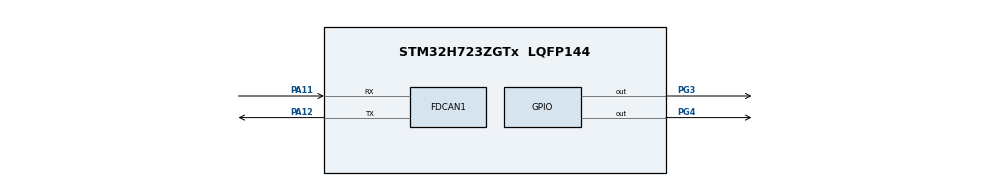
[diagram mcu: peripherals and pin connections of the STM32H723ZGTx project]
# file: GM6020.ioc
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CORTEX_M7.default_mode_Activation=1
FDCAN1.AutoRetransmission=ENABLE
FDCAN1.CalculateBaudRateNominal=1000000
FDCAN1.CalculateTimeBitNominal=1000
FDCAN1.CalculateTimeQuantumNominal=8.0
FDCAN1.NominalPrescaler=1
FDCAN1.NominalTimeSeg1=99
FDCAN1.NominalTimeSeg2=25
FDCAN1.RxFifo0ElmtsNbr=1
FDCAN1.StdFiltersNbr=1
FDCAN1.TxFifoQueueElmtsNbr=1
Mcu.Family=STM32H7
Mcu.Name=STM32H723ZGTx
Mcu.Package=LQFP144
NVIC.FDCAN1_IT0_IRQn=true\:0\:0\:false\:false\:true\:true\:true\:true
NVIC.PriorityGroup=NVIC_PRIORITYGROUP_4
PA11.Mode=FDCAN_Activate
PA11.Signal=FDCAN1_RX
PA12.Mode=FDCAN_Activate
PA12.Signal=FDCAN1_TX
PA13(JTMS/SWDIO).Mode=Serial_Wire
PA13(JTMS/SWDIO).Signal=DEBUG_JTMS-SWDIO
PA14(JTCK/SWCLK).Mode=Serial_Wire
PA14(JTCK/SWCLK).Signal=DEBUG_JTCK-SWCLK
PG3.PinState=GPIO_PIN_RESET
PG3.Signal=GPIO_Output
PG4.GPIO_Speed=GPIO_SPEED_FREQ_LOW
PG4.Signal=GPIO_Output
PH0-OSC_IN.Mode=HSE-External-Oscillator
PH0-OSC_IN.Signal=RCC_OSC_IN
PH1-OSC_OUT.Mode=HSE-External-Oscillator
PH1-OSC_OUT.Signal=RCC_OSC_OUT
ProjectManager.HeapSize=0x200
ProjectManager.StackSize=0x400
ProjectManager.TargetToolchain=STM32CubeIDE
RCC.ADCFreq_Value=50390625
RCC.APB1Freq_Value=125000000
RCC.APB2Freq_Value=125000000
RCC.APB3Freq_Value=125000000
RCC.APB4Freq_Value=125000000
RCC.CortexFreq_Value=500000000
RCC.D1PPRE=RCC_APB3_DIV2
RCC.D2PPRE1=RCC_APB1_DIV2
RCC.D2PPRE2=RCC_APB2_DIV2
RCC.D3PPRE=RCC_APB4_DIV2
RCC.DIVM1=2
RCC.DIVN1=40
RCC.DIVP1=1
RCC.DIVQ1=4
RCC.HCLKFreq_Value=250000000
RCC.HPRE=RCC_HCLK_DIV2
RCC.PLLFRACN=0
RCC.PLLSourceVirtual=RCC_PLLSOURCE_HSE
RCC.SYSCLKFreq_VALUE=500000000
RCC.SYSCLKSource=RCC_SYSCLKSOURCE_PLLCLK
RCC.USBFreq_Value=125000000
VP_MEMORYMAP_VS_MEMORYMAP.Mode=CurAppReg
board=custom

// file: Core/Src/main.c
/* USER CODE BEGIN Header */
/**
  ******************************************************************************
  * @file           : main.c
  * @brief          : Main program body
  ******************************************************************************
  * @attention
  *
  * Copyright (c) 2026 STMicroelectronics.
  * All rights reserved.
  *
  * This software is licensed under terms that can be found in the LICENSE file
  * in the root directory of this software component.
  * If no LICENSE file comes with this software, it is provided AS-IS.
  *
  ******************************************************************************
  */
/* USER CODE END Header */
#include "main.h"
#include "GM6020.h"

FDCAN_HandleTypeDef hfdcan1;

void SystemClock_Config(void);
static void MPU_Config(void);
static void MX_GPIO_Init(void);
static void MX_FDCAN1_Init(void);

int main(void)
{

  /* MPU Configuration--------------------------------------------------------*/
  MPU_Config();

  /* MCU Configuration--------------------------------------------------------*/

  /* Reset of all peripherals, Initializes the Flash interface and the Systick. */
  HAL_Init();

  /* Configure the system clock */
  SystemClock_Config();

  /* Initialize all configured peripherals */
  MX_GPIO_Init();
  MX_FDCAN1_Init();
  /* USER CODE BEGIN 2 */

  GM6020_Init();
  HAL_Delay(3000);

  HAL_GPIO_WritePin(GPIOG, GPIO_PIN_4, GPIO_PIN_SET);

  HAL_Delay(1000);

  //让电机转 180°
  GM6020_Turn_Degrees(180.0f);

//在等待循环中持续调用GM6020_Update
  uint32_t timeout = 3000;  // 最多等待3秒(超时保护)
  while (fabsf(GM6020_Get_Target_Angle() - GM6020_Get_Current_Angle()) > 1.0f && timeout > 0) {
      GM6020_Update();
      HAL_Delay(1);
      timeout--;
  }

  //额外等1s确保电机到位
  HAL_Delay(1000);

  HAL_GPIO_WritePin(GPIOG, GPIO_PIN_4, GPIO_PIN_RESET);
  /* USER CODE END 2 */

  /* Infinite loop */
  /* USER CODE BEGIN WHILE */
  while (1)
  {
	  GM6020_Update();
	  HAL_Delay(1);
    /* USER CODE END WHILE */

  }
}

void SystemClock_Config(void)
{
  RCC_OscInitTypeDef RCC_OscInitStruct = {0};
  RCC_ClkInitTypeDef RCC_ClkInitStruct = {0};

  /** Supply configuration update enable
  */
  HAL_PWREx_ConfigSupply(PWR_LDO_SUPPLY);

  /** Configure the main internal regulator output voltage
  */
  __HAL_PWR_VOLTAGESCALING_CONFIG(PWR_REGULATOR_VOLTAGE_SCALE0);

  while(!__HAL_PWR_GET_FLAG(PWR_FLAG_VOSRDY)) {}

  /** Initializes the RCC Oscillators according to the specified parameters
  * in the RCC_OscInitTypeDef structure.
  */
  RCC_OscInitStruct.OscillatorType = RCC_OSCILLATORTYPE_HSE;
  RCC_OscInitStruct.HSEState = RCC_HSE_ON;
  RCC_OscInitStruct.PLL.PLLState = RCC_PLL_ON;
  RCC_OscInitStruct.PLL.PLLSource = RCC_PLLSOURCE_HSE;
  RCC_OscInitStruct.PLL.PLLM = 2;
  RCC_OscInitStruct.PLL.PLLN = 40;
  RCC_OscInitStruct.PLL.PLLP = 1;
  RCC_OscInitStruct.PLL.PLLQ = 4;
  RCC_OscInitStruct.PLL.PLLR = 2;
  RCC_OscInitStruct.PLL.PLLRGE = RCC_PLL1VCIRANGE_3;
  RCC_OscInitStruct.PLL.PLLVCOSEL = RCC_PLL1VCOWIDE;
  RCC_OscInitStruct.PLL.PLLFRACN = 0;
  if (HAL_RCC_OscConfig(&RCC_OscInitStruct) != HAL_OK)
  {
    Error_Handler();
  }

  /** Initializes the CPU, AHB and APB buses clocks
  */
  RCC_ClkInitStruct.ClockType = RCC_CLOCKTYPE_HCLK|RCC_CLOCKTYPE_SYSCLK
                              |RCC_CLOCKTYPE_PCLK1|RCC_CLOCKTYPE_PCLK2
                              |RCC_CLOCKTYPE_D3PCLK1|RCC_CLOCKTYPE_D1PCLK1;
  RCC_ClkInitStruct.SYSCLKSource = RCC_SYSCLKSOURCE_PLLCLK;
  RCC_ClkInitStruct.SYSCLKDivider = RCC_SYSCLK_DIV1;
  RCC_ClkInitStruct.AHBCLKDivider = RCC_HCLK_DIV2;
  RCC_ClkInitStruct.APB3CLKDivider = RCC_APB3_DIV2;
  RCC_ClkInitStruct.APB1CLKDivider = RCC_APB1_DIV2;
  RCC_ClkInitStruct.APB2CLKDivider = RCC_APB2_DIV2;
  RCC_ClkInitStruct.APB4CLKDivider = RCC_APB4_DIV2;

  if (HAL_RCC_ClockConfig(&RCC_ClkInitStruct, FLASH_LATENCY_3) != HAL_OK)
  {
    Error_Handler();
  }
}

static void MX_FDCAN1_Init(void)
{

  hfdcan1.Instance = FDCAN1;
  hfdcan1.Init.FrameFormat = FDCAN_FRAME_CLASSIC;
  hfdcan1.Init.Mode = FDCAN_MODE_NORMAL;
  hfdcan1.Init.AutoRetransmission = ENABLE;
  hfdcan1.Init.TransmitPause = DISABLE;
  hfdcan1.Init.ProtocolException = DISABLE;
  hfdcan1.Init.NominalPrescaler = 1;
  hfdcan1.Init.NominalSyncJumpWidth = 1;
  hfdcan1.Init.NominalTimeSeg1 = 99;
  hfdcan1.Init.NominalTimeSeg2 = 25;
  hfdcan1.Init.DataPrescaler = 1;
  hfdcan1.Init.DataSyncJumpWidth = 1;
  hfdcan1.Init.DataTimeSeg1 = 1;
  hfdcan1.Init.DataTimeSeg2 = 1;
  hfdcan1.Init.MessageRAMOffset = 0;
  hfdcan1.Init.StdFiltersNbr = 1;
  hfdcan1.Init.ExtFiltersNbr = 0;
  hfdcan1.Init.RxFifo0ElmtsNbr = 1;
  hfdcan1.Init.RxFifo0ElmtSize = FDCAN_DATA_BYTES_8;
  hfdcan1.Init.RxFifo1ElmtsNbr = 0;
  hfdcan1.Init.RxFifo1ElmtSize = FDCAN_DATA_BYTES_8;
  hfdcan1.Init.RxBuffersNbr = 0;
  hfdcan1.Init.RxBufferSize = FDCAN_DATA_BYTES_8;
  hfdcan1.Init.TxEventsNbr = 0;
  hfdcan1.Init.TxBuffersNbr = 0;
  hfdcan1.Init.TxFifoQueueElmtsNbr = 1;
  hfdcan1.Init.TxFifoQueueMode = FDCAN_TX_FIFO_OPERATION;
  hfdcan1.Init.TxElmtSize = FDCAN_DATA_BYTES_8;
  if (HAL_FDCAN_Init(&hfdcan1) != HAL_OK)
  {
    Error_Handler();
  }

}

static void MX_GPIO_Init(void)
{
  GPIO_InitTypeDef GPIO_InitStruct = {0};

  /* GPIO Ports Clock Enable */
  __HAL_RCC_GPIOH_CLK_ENABLE();
  __HAL_RCC_GPIOG_CLK_ENABLE();
  __HAL_RCC_GPIOA_CLK_ENABLE();

  /*Configure GPIO pin Output Level */
  HAL_GPIO_WritePin(GPIOG, GPIO_PIN_3|GPIO_PIN_4, GPIO_PIN_RESET);

  /*Configure GPIO pins : PG3 PG4 */
  GPIO_InitStruct.Pin = GPIO_PIN_3|GPIO_PIN_4;
  GPIO_InitStruct.Mode = GPIO_MODE_OUTPUT_PP;
  GPIO_InitStruct.Pull = GPIO_NOPULL;
  GPIO_InitStruct.Speed = GPIO_SPEED_FREQ_LOW;
  HAL_GPIO_Init(GPIOG, &GPIO_InitStruct);

}

 /* MPU Configuration */

void MPU_Config(void)
{
  MPU_Region_InitTypeDef MPU_InitStruct = {0};

  /* Disables the MPU */
  HAL_MPU_Disable();

  /** Initializes and configures the Region and the memory to be protected
  */
  MPU_InitStruct.Enable = MPU_REGION_ENABLE;
  MPU_InitStruct.Number = MPU_REGION_NUMBER0;
  MPU_InitStruct.BaseAddress = 0x0;
  MPU_InitStruct.Size = MPU_REGION_SIZE_4GB;
  MPU_InitStruct.SubRegionDisable = 0x87;
  MPU_InitStruct.TypeExtField = MPU_TEX_LEVEL0;
  MPU_InitStruct.AccessPermission = MPU_REGION_NO_ACCESS;
  MPU_InitStruct.DisableExec = MPU_INSTRUCTION_ACCESS_DISABLE;
  MPU_InitStruct.IsShareable = MPU_ACCESS_SHAREABLE;
  MPU_InitStruct.IsCacheable = MPU_ACCESS_NOT_CACHEABLE;
  MPU_InitStruct.IsBufferable = MPU_ACCESS_NOT_BUFFERABLE;

  HAL_MPU_ConfigRegion(&MPU_InitStruct);
  /* Enables the MPU */
  HAL_MPU_Enable(MPU_PRIVILEGED_DEFAULT);

}

void Error_Handler(void)
{
  __disable_irq();
  while (1)
  {
  }
}
